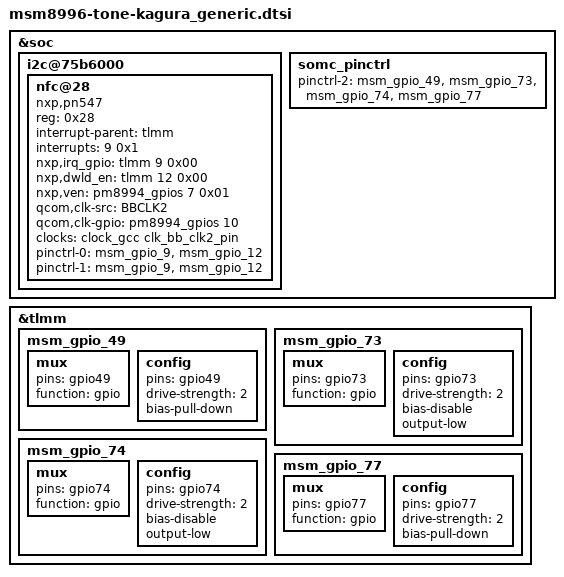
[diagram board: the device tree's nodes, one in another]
/* arch/arm/boot/dts/qcom/msm8996-tone-kagura_generic.dtsi
 *
 * This program is free software; you can redistribute it and/or modify
 * it under the terms of the GNU General Public License version 2 and
 * only version 2 as published by the Free Software Foundation.
 *
 * This program is distributed in the hope that it will be useful,
 * but WITHOUT ANY WARRANTY; without even the implied warranty of
 * MERCHANTABILITY or FITNESS FOR A PARTICULAR PURPOSE.  See the
 * GNU General Public License for more details.
 */
/*
 * Copyright (C) 2016 Sony Mobile Communications Inc.
 *
 * This program is free software; you can redistribute it and/or modify
 * it under the terms of the GNU General Public License version 2, as
 * published by the Free Software Foundation.
 */

&soc {
	 /*I2C : BLSP8 */
	i2c@75b6000 { /* BLSP2 QUP1 */
		nfc@28 {
			compatible = "nxp,pn547";
			reg = <0x28>;
			interrupt-parent = <&tlmm>;
			interrupts = <9 0x1>;
			nxp,irq_gpio = <&tlmm 9 0x00>;
			nxp,dwld_en = <&tlmm 12 0x00>;
			nxp,ven = <&pm8994_gpios 7 0x01>;
			qcom,clk-src = "BBCLK2";
			qcom,clk-gpio = <&pm8994_gpios 10 0x00>;
			clocks = <&clock_gcc clk_bb_clk2_pin>;
			clock-names = "nfc_clk";
			pinctrl-names = "pn547-active", "pn547-inactive";
			pinctrl-0 = <&msm_gpio_9 &msm_gpio_12>;
			pinctrl-1 = <&msm_gpio_9 &msm_gpio_12>;
		};
	};

	somc_pinctrl: somc_pinctrl {
		/* If variant specific default setting is needed,
		   fill pinctrl-2 value in <variant>.dtsi */
		pinctrl-2 = <&msm_gpio_49 &msm_gpio_73 &msm_gpio_74
				&msm_gpio_77>;
	};
};

&tlmm {
	/* GPIO_49 : NC */
	msm_gpio_49: msm_gpio_49 {
		mux {
			pins = "gpio49";
			function = "gpio";
		};

		config {
			pins = "gpio49";
			drive-strength = <2>;
			/delete-property/ bias-pull-up;
			bias-pull-down;
		};
	};

	/* GPIO_73 : NC */
	msm_gpio_73: msm_gpio_73 {
		mux {
			pins = "gpio73";
			function = "gpio";
		};

		config {
			pins = "gpio73";
			drive-strength = <2>;
			bias-disable;
			output-low;
		};
	};

	/* GPIO_74 : NC */
	msm_gpio_74: msm_gpio_74 {
		mux {
			pins = "gpio74";
			function = "gpio";
		};

		config {
			pins = "gpio74";
			drive-strength = <2>;
			bias-disable;
			output-low;
		};
	};

	/* GPIO_77 : NC */
	msm_gpio_77: msm_gpio_77 {
		mux {
			pins = "gpio77";
			function = "gpio";
		};

		config {
			pins = "gpio77";
			drive-strength = <2>;
			bias-pull-down;
		};
	};
};
